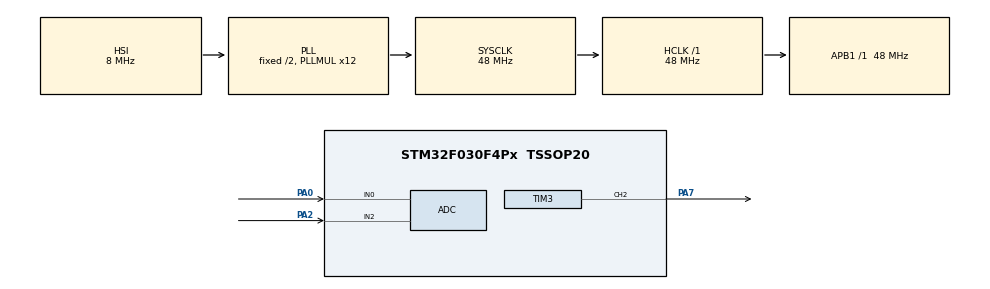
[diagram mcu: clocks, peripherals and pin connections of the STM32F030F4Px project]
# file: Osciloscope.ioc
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ADC.ClockPrescaler=ADC_CLOCK_ASYNC_DIV1
ADC.ContinuousConvMode=ENABLE
ADC.DMAContinuousRequests=ENABLE
ADC.EOCSelection=ADC_EOC_SEQ_CONV
ADC.SamplingTime=ADC_SAMPLETIME_239CYCLES_5
Dma.ADC.0.Direction=DMA_PERIPH_TO_MEMORY
Dma.ADC.0.Instance=DMA1_Channel1
Dma.ADC.0.MemDataAlignment=DMA_MDATAALIGN_HALFWORD
Dma.ADC.0.MemInc=DMA_MINC_ENABLE
Dma.ADC.0.Mode=DMA_CIRCULAR
Dma.ADC.0.PeriphDataAlignment=DMA_PDATAALIGN_HALFWORD
Dma.ADC.0.PeriphInc=DMA_PINC_DISABLE
Dma.ADC.0.Priority=DMA_PRIORITY_LOW
Dma.Request0=ADC
Mcu.Family=STM32F0
Mcu.Name=STM32F030F4Px
Mcu.Package=TSSOP20
NVIC.DMA1_Channel1_IRQn=true\:0\:0\:false\:false\:true\:false\:true\:true
PA0.Mode=IN0
PA0.Signal=ADC_IN0
PA1.Signal=ADC_IN1
PA13.Mode=Serial_Wire
PA13.Signal=SYS_SWDIO
PA14.Mode=Serial_Wire
PA14.Signal=SYS_SWCLK
PA2.Mode=IN2
PA2.Signal=ADC_IN2
PA7.Signal=S_TIM3_CH2
PF0-OSC_IN.Mode=HSE-External-Oscillator
PF0-OSC_IN.Signal=RCC_OSC_IN
PF1-OSC_OUT.Mode=HSE-External-Oscillator
PF1-OSC_OUT.Signal=RCC_OSC_OUT
ProjectManager.HeapSize=0x200
ProjectManager.StackSize=0x400
ProjectManager.TargetToolchain=STM32CubeIDE
RCC.AHBFreq_Value=48000000
RCC.APB1Freq_Value=48000000
RCC.APB1TimFreq_Value=48000000
RCC.HCLKFreq_Value=48000000
RCC.PLLMUL=RCC_PLL_MUL12
RCC.SYSCLKFreq_VALUE=48000000
RCC.SYSCLKSource=RCC_SYSCLKSOURCE_PLLCLK
SH.S_TIM3_CH2.0=TIM3_CH2,PWM Generation2 CH2
TIM3.AutoReloadPreload=TIM_AUTORELOAD_PRELOAD_ENABLE
TIM3.Channel-PWM\ Generation2\ CH2=TIM_CHANNEL_2
TIM3.Period=256
TIM3.Prescaler=655
TIM3.Pulse-PWM\ Generation2\ CH2=128
VP_ADC_TempSens_Input.Mode=IN-TempSens
board=custom

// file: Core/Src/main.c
/* USER CODE BEGIN Header */
/**
  ******************************************************************************
  * @file           : main.c
  * @brief          : Main program body
  ******************************************************************************
  * @attention
  *
  * <h2><center>&copy; Copyright (c) 2022 STMicroelectronics.
  * All rights reserved.</center></h2>
  *
  * This software component is licensed by ST under BSD 3-Clause license,
  * the "License"; You may not use this file except in compliance with the
  * License. You may obtain a copy of the License at:
  *                        opensource.org/licenses/BSD-3-Clause
  *
  ******************************************************************************
  */
/* USER CODE END Header */
#include "main.h"

/* USER CODE BEGIN PD */
#define ADC_BUF_LEN 3
uint32_t tCelsius;

uint32_t tFahrenheit;

uint32_t tCelsius2;
/* USER CODE END PD */

 ADC_HandleTypeDef hadc;
DMA_HandleTypeDef hdma_adc;

TIM_HandleTypeDef htim3;

/* USER CODE BEGIN PV */
uint16_t adc_buf[3];
/* USER CODE END PV */

void SystemClock_Config(void);
static void MX_GPIO_Init(void);
static void MX_ADC_Init(void);
static void MX_DMA_Init(void);
static void MX_TIM3_Init(void);
/* USER CODE BEGIN PFP */
uint8_t my_flag;
uint16_t raw;
uint16_t rawwww;
/* USER CODE END PFP */

int main(void)
{

  /* MCU Configuration--------------------------------------------------------*/

  /* Reset of all peripherals, Initializes the Flash interface and the Systick. */
os.c  HAL_Init();

  /* Configure the system clock */
  SystemClock_Config();

  /* USER CODE BEGIN SysInit */
  MX_DMA_Init();
  /* USER CODE END SysInit */

  /* Initialize all configured peripherals */
  MX_GPIO_Init();
  MX_ADC_Init();
  MX_DMA_Init();
  MX_TIM3_Init();
  /* USER CODE BEGIN 2 */

  //******1-----DMA_init should be above ADC_init************
  //******2-----Sampling time should be high************

//HAL_TIM_PWM_Start(&htim3, TIM_CHANNEL_2);
//
HAL_ADCEx_Calibration_Start(&hadc);
HAL_ADC_Start_DMA(&hadc,(uint32_t*) adc_buf, 3);

//uint16_t readValue;

//
//HAL_ADC_Start(&hadc);
//
//HAL_ADC_PollForConversion(&hadc, HAL_MAX_DELAY);
//__HAL_TIM_SET_COMPARE(&htim3,TIM_CHANNEL_2, 100);
//int x;
  /* USER CODE END 2 */

  /* Infinite loop */
  /* USER CODE BEGIN WHILE */
  while (1)
  {
	    HAL_ADCEx_Calibration_Start(&hadc);
//	    HAL_ADC_PollForConversion(&hadc,1000);
//	    readValue = HAL_ADC_GetValue(&hadc);
	    tCelsius = (uint32_t)(357 - 0.187364 * (float)adc_buf[2]);

	    tFahrenheit = (uint32_t)((float)adc_buf[0]*0.322);
	    tCelsius2 = (uint32_t)((float)adc_buf[1]*0.322);
//      raw++;

//		for(int x=0; x<250; x=x+1)
//		{
//		  __HAL_TIM_SET_COMPARE(&htim3,TIM_CHANNEL_2, x);
//		  HAL_Delay(20);
////		  raw=HAL_ADC_GetValue(&hadc);
//		}
//		for(int x=250; x>0; x=x-1)
//		{
//		  __HAL_TIM_SET_COMPARE(&htim3,TIM_CHANNEL_2, x);
//		  HAL_Delay(20);
////		  raw=HAL_ADC_GetValue(&hadc);
//		}

    /* USER CODE END WHILE */

  }
}

void SystemClock_Config(void)
{
  RCC_OscInitTypeDef RCC_OscInitStruct = {0};
  RCC_ClkInitTypeDef RCC_ClkInitStruct = {0};

  /** Initializes the RCC Oscillators according to the specified parameters
  * in the RCC_OscInitTypeDef structure.
  */
  RCC_OscInitStruct.OscillatorType = RCC_OSCILLATORTYPE_HSI|RCC_OSCILLATORTYPE_HSI14;
  RCC_OscInitStruct.HSIState = RCC_HSI_ON;
  RCC_OscInitStruct.HSI14State = RCC_HSI14_ON;
  RCC_OscInitStruct.HSICalibrationValue = RCC_HSICALIBRATION_DEFAULT;
  RCC_OscInitStruct.HSI14CalibrationValue = 16;
  RCC_OscInitStruct.PLL.PLLState = RCC_PLL_ON;
  RCC_OscInitStruct.PLL.PLLSource = RCC_PLLSOURCE_HSI;
  RCC_OscInitStruct.PLL.PLLMUL = RCC_PLL_MUL12;
  RCC_OscInitStruct.PLL.PREDIV = RCC_PREDIV_DIV1;
  if (HAL_RCC_OscConfig(&RCC_OscInitStruct) != HAL_OK)
  {
    Error_Handler();
  }

  /** Initializes the CPU, AHB and APB buses clocks
  */
  RCC_ClkInitStruct.ClockType = RCC_CLOCKTYPE_HCLK|RCC_CLOCKTYPE_SYSCLK
                              |RCC_CLOCKTYPE_PCLK1;
  RCC_ClkInitStruct.SYSCLKSource = RCC_SYSCLKSOURCE_PLLCLK;
  RCC_ClkInitStruct.AHBCLKDivider = RCC_SYSCLK_DIV1;
  RCC_ClkInitStruct.APB1CLKDivider = RCC_HCLK_DIV1;

  if (HAL_RCC_ClockConfig(&RCC_ClkInitStruct, FLASH_LATENCY_1) != HAL_OK)
  {
    Error_Handler();
  }
}

static void MX_ADC_Init(void)
{

  ADC_ChannelConfTypeDef sConfig = {0};

  /** Configure the global features of the ADC (Clock, Resolution, Data Alignment and number of conversion)
  */
  hadc.Instance = ADC1;
  hadc.Init.ClockPrescaler = ADC_CLOCK_ASYNC_DIV1;
  hadc.Init.Resolution = ADC_RESOLUTION_12B;
  hadc.Init.DataAlign = ADC_DATAALIGN_RIGHT;
  hadc.Init.ScanConvMode = ADC_SCAN_DIRECTION_FORWARD;
  hadc.Init.EOCSelection = ADC_EOC_SEQ_CONV;
  hadc.Init.LowPowerAutoWait = DISABLE;
  hadc.Init.LowPowerAutoPowerOff = DISABLE;
  hadc.Init.ContinuousConvMode = ENABLE;
  hadc.Init.DiscontinuousConvMode = DISABLE;
  hadc.Init.ExternalTrigConv = ADC_SOFTWARE_START;
  hadc.Init.ExternalTrigConvEdge = ADC_EXTERNALTRIGCONVEDGE_NONE;
  hadc.Init.DMAContinuousRequests = ENABLE;
  hadc.Init.Overrun = ADC_OVR_DATA_PRESERVED;
  if (HAL_ADC_Init(&hadc) != HAL_OK)
  {
    Error_Handler();
  }

  /** Configure for the selected ADC regular channel to be converted.
  */
  sConfig.Channel = ADC_CHANNEL_0;
  sConfig.Rank = ADC_RANK_CHANNEL_NUMBER;
  sConfig.SamplingTime = ADC_SAMPLETIME_239CYCLES_5;
  if (HAL_ADC_ConfigChannel(&hadc, &sConfig) != HAL_OK)
  {
    Error_Handler();
  }

  /** Configure for the selected ADC regular channel to be converted.
  */
  sConfig.Channel = ADC_CHANNEL_2;
  if (HAL_ADC_ConfigChannel(&hadc, &sConfig) != HAL_OK)
  {
    Error_Handler();
  }

  /** Configure for the selected ADC regular channel to be converted.
  */
  sConfig.Channel = ADC_CHANNEL_TEMPSENSOR;
  if (HAL_ADC_ConfigChannel(&hadc, &sConfig) != HAL_OK)
  {
    Error_Handler();
  }

}

static void MX_TIM3_Init(void)
{

  TIM_MasterConfigTypeDef sMasterConfig = {0};
  TIM_OC_InitTypeDef sConfigOC = {0};

  htim3.Instance = TIM3;
  htim3.Init.Prescaler = 655;
  htim3.Init.CounterMode = TIM_COUNTERMODE_UP;
  htim3.Init.Period = 256;
  htim3.Init.ClockDivision = TIM_CLOCKDIVISION_DIV1;
  htim3.Init.AutoReloadPreload = TIM_AUTORELOAD_PRELOAD_ENABLE;
  if (HAL_TIM_PWM_Init(&htim3) != HAL_OK)
  {
    Error_Handler();
  }
  sMasterConfig.MasterOutputTrigger = TIM_TRGO_RESET;
  sMasterConfig.MasterSlaveMode = TIM_MASTERSLAVEMODE_DISABLE;
  if (HAL_TIMEx_MasterConfigSynchronization(&htim3, &sMasterConfig) != HAL_OK)
  {
    Error_Handler();
  }
  sConfigOC.OCMode = TIM_OCMODE_PWM1;
  sConfigOC.Pulse = 128;
  sConfigOC.OCPolarity = TIM_OCPOLARITY_HIGH;
  sConfigOC.OCFastMode = TIM_OCFAST_DISABLE;
  if (HAL_TIM_PWM_ConfigChannel(&htim3, &sConfigOC, TIM_CHANNEL_2) != HAL_OK)
  {
    Error_Handler();
  }
  HAL_TIM_MspPostInit(&htim3);

}

static void MX_DMA_Init(void)
{

  /* DMA controller clock enable */
  __HAL_RCC_DMA1_CLK_ENABLE();

  /* DMA interrupt init */
  /* DMA1_Channel1_IRQn interrupt configuration */
  HAL_NVIC_SetPriority(DMA1_Channel1_IRQn, 0, 0);
  HAL_NVIC_EnableIRQ(DMA1_Channel1_IRQn);

}

static void MX_GPIO_Init(void)
{

  /* GPIO Ports Clock Enable */
  __HAL_RCC_GPIOF_CLK_ENABLE();
  __HAL_RCC_GPIOA_CLK_ENABLE();

}

/* USER CODE BEGIN 4 */
// Called when first half of buffer is filled
//void HAL_ADC_ConvHalfCpltCallback(ADC_HandleTypeDef* hadc) {
////  HAL_GPIO_WritePin(LED_GPIO_Port, LED_Pin, GPIO_PIN_SET);
//
//}

// Called when buffer is completely filled
void HAL_ADC_ConvCpltCallback(ADC_HandleTypeDef* hadc) {
//  HAL_GPIO_WritePin(LED_GPIO_Port, LED_Pin, GPIO_PIN_RESET);
//	  HAL_ADC_Start_DMA(&hadc, adc_buf, 1);
//	raw=adc_buf[0];

}

/* USER CODE END 4 */

void Error_Handler(void)
{
  __disable_irq();
  while (1)
  {
  }
}
